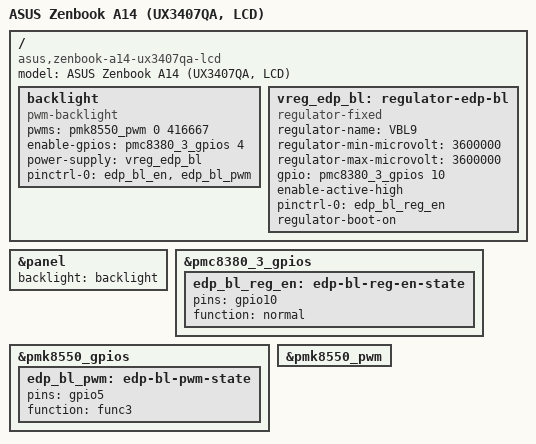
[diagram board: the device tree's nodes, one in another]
// SPDX-License-Identifier: BSD-3-Clause
/*
 * Copyright (c) 2025 Qualcomm Innovation Center, Inc. All rights reserved.
 * Copyright (c) 2025 Aleksandrs Vinarskis <alex@vinarskis.com>
 */

/dts-v1/;

#include "x1p42100-asus-zenbook-a14.dtsi"

/ {
	model = "ASUS Zenbook A14 (UX3407QA, LCD)";
	compatible = "asus,zenbook-a14-ux3407qa-lcd", "asus,zenbook-a14-ux3407qa", "qcom,x1p42100";

	backlight: backlight {
		compatible = "pwm-backlight";
		pwms = <&pmk8550_pwm 0 416667>;
		enable-gpios = <&pmc8380_3_gpios 4 GPIO_ACTIVE_HIGH>;
		power-supply = <&vreg_edp_bl>;

		pinctrl-0 = <&edp_bl_en>, <&edp_bl_pwm>;
		pinctrl-names = "default";
	};

	vreg_edp_bl: regulator-edp-bl {
		compatible = "regulator-fixed";

		regulator-name = "VBL9";
		regulator-min-microvolt = <3600000>;
		regulator-max-microvolt = <3600000>;

		gpio = <&pmc8380_3_gpios 10 GPIO_ACTIVE_HIGH>;
		enable-active-high;

		pinctrl-0 = <&edp_bl_reg_en>;
		pinctrl-names = "default";

		regulator-boot-on;
	};
};

&panel {
	backlight = <&backlight>;
};

&pmc8380_3_gpios {
	edp_bl_reg_en: edp-bl-reg-en-state {
		pins = "gpio10";
		function = "normal";
	};
};

&pmk8550_gpios {
	edp_bl_pwm: edp-bl-pwm-state {
		pins = "gpio5";
		function = "func3";
	};
};

&pmk8550_pwm {
	status = "okay";
};
